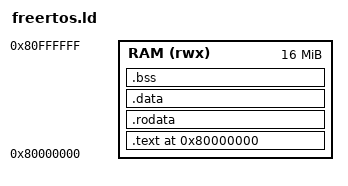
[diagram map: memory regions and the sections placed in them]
ENTRY(_start)

MEMORY
{
    RAM (rwx) : ORIGIN = 0x80000000, LENGTH = 16M
}

SECTIONS
{
    . = ORIGIN(RAM);

    .text : {
        *(.text*)
    } > RAM

    .rodata : {
        *(.rodata*)
    } > RAM

    .data : {
        *(.data*)
    } > RAM

    .bss : {
        __bss_start = .;
        *(.bss*)
        __bss_end = .;
    } > RAM

    . = ALIGN(16);
    _stack_top = . + 0x4000;
}
